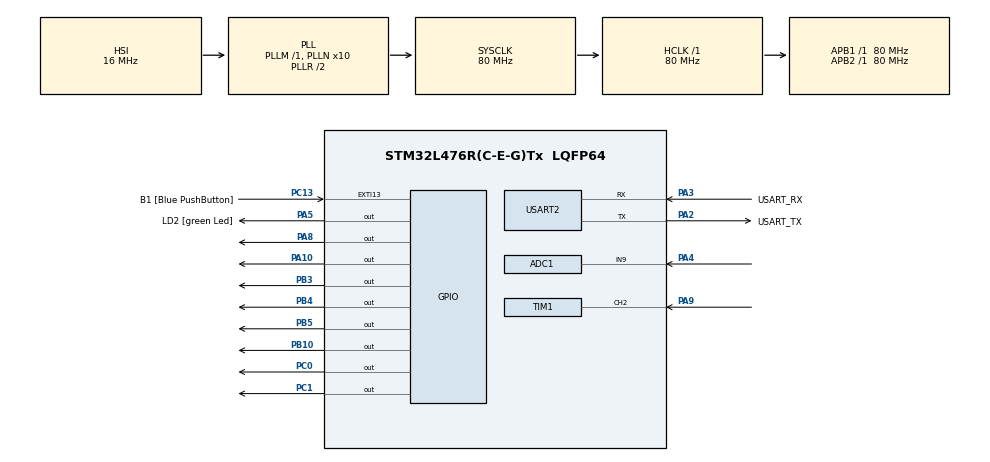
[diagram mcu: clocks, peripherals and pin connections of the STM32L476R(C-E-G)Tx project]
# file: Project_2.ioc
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ADC1.Channel-0\#ChannelRegularConversion=ADC_CHANNEL_9
ADC1.ClockPrescaler=ADC_CLOCK_ASYNC_DIV256
ADC1.ContinuousConvMode=ENABLE
ADC1.NbrOfConversionFlag=1
ADC1.OffsetNumber-0\#ChannelRegularConversion=ADC_OFFSET_NONE
ADC1.Rank-0\#ChannelRegularConversion=1
ADC1.SamplingTime-0\#ChannelRegularConversion=ADC_SAMPLETIME_2CYCLES_5
ADC1.master=1
Mcu.Family=STM32L4
Mcu.Name=STM32L476R(C-E-G)Tx
Mcu.Package=LQFP64
NVIC.ADC1_2_IRQn=true\:0\:0\:false\:true\:true\:1\:true\:true
NVIC.PriorityGroup=NVIC_PRIORITYGROUP_4
NVIC.TIM1_CC_IRQn=true\:0\:0\:false\:true\:true\:2\:true\:true
NVIC.TIM6_DAC_IRQn=true\:0\:0\:false\:true\:true\:4\:true\:true
NVIC.USART2_IRQn=true\:0\:0\:false\:true\:true\:3\:true\:true
PA10.Signal=GPIO_Output
PA13\ (JTMS-SWDIO).GPIO_Label=TMS
PA13\ (JTMS-SWDIO).Mode=Serial_Wire
PA13\ (JTMS-SWDIO).Signal=SYS_JTMS-SWDIO
PA14\ (JTCK-SWCLK).GPIO_Label=TCK
PA14\ (JTCK-SWCLK).Mode=Serial_Wire
PA14\ (JTCK-SWCLK).Signal=SYS_JTCK-SWCLK
PA2.GPIO_Label=USART_TX
PA2.GPIO_Mode=GPIO_MODE_AF_PP
PA2.GPIO_PuPd=GPIO_NOPULL
PA2.GPIO_Speed=GPIO_SPEED_FREQ_VERY_HIGH
PA2.Mode=Asynchronous
PA2.Signal=USART2_TX
PA3.GPIO_Label=USART_RX
PA3.GPIO_Mode=GPIO_MODE_AF_PP
PA3.GPIO_PuPd=GPIO_NOPULL
PA3.GPIO_Speed=GPIO_SPEED_FREQ_VERY_HIGH
PA3.Mode=Asynchronous
PA3.Signal=USART2_RX
PA4.Signal=ADCx_IN9
PA5.GPIO_Label=LD2 [green Led]
PA5.GPIO_ModeDefaultOutputPP=GPIO_MODE_OUTPUT_PP
PA5.GPIO_PuPd=GPIO_NOPULL
PA5.GPIO_Speed=GPIO_SPEED_FREQ_LOW
PA5.Signal=GPIO_Output
PA8.Signal=GPIO_Output
PA9.Signal=S_TIM1_CH2
PB10.Signal=GPIO_Output
PB3\ (JTDO-TRACESWO).Signal=GPIO_Output
PB4\ (NJTRST).Signal=GPIO_Output
PB5.Signal=GPIO_Output
PC0.Signal=GPIO_Output
PC1.Signal=GPIO_Output
PC13.GPIO_Label=B1 [Blue PushButton]
PC13.GPIO_ModeDefaultEXTI=GPIO_MODE_IT_FALLING
PC13.GPIO_PuPd=GPIO_NOPULL
PC13.Signal=GPXTI13
PC14-OSC32_IN\ (PC14).Mode=LSE-External-Oscillator
PC14-OSC32_IN\ (PC14).Signal=RCC_OSC32_IN
PC15-OSC32_OUT\ (PC15).Mode=LSE-External-Oscillator
PC15-OSC32_OUT\ (PC15).Signal=RCC_OSC32_OUT
PH0-OSC_IN\ (PH0).Signal=RCC_OSC_IN
PH1-OSC_OUT\ (PH1).Signal=RCC_OSC_OUT
ProjectManager.HeapSize=0x200
ProjectManager.StackSize=0x400
ProjectManager.TargetToolchain=STM32CubeIDE
RCC.ADCFreq_Value=64000000
RCC.AHBFreq_Value=80000000
RCC.APB1Freq_Value=80000000
RCC.APB1TimFreq_Value=80000000
RCC.APB2Freq_Value=80000000
RCC.APB2TimFreq_Value=80000000
RCC.CortexFreq_Value=80000000
RCC.HCLKFreq_Value=80000000
RCC.HSE_VALUE=8000000
RCC.HSI_VALUE=16000000
RCC.MSI_VALUE=4000000
RCC.PLLN=10
RCC.PLLSourceVirtual=RCC_PLLSOURCE_HSI
RCC.PREFETCH_ENABLE=1
RCC.SYSCLKFreq_VALUE=80000000
RCC.SYSCLKSource=RCC_SYSCLKSOURCE_PLLCLK
RCC.USBFreq_Value=64000000
RCC.VCOOutputFreq_Value=160000000
SH.ADCx_IN9.0=ADC1_IN9,IN9-Single-Ended
SH.S_TIM1_CH2.0=TIM1_CH2,Input_Capture2_from_TI2
TIM1.Channel-Input_Capture2_from_TI2=TIM_CHANNEL_2
TIM1.Period=0xFFFF
TIM1.Prescaler=80-1
TIM6.Period=0xFFFF
TIM6.Prescaler=80-1
USART2.VirtualMode-Asynchronous=VM_ASYNC
VP_TIM6_VS_ClockSourceINT.Mode=Enable_Timer
board=NUCLEO-L476RG

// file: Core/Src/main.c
#include "main.h"

typedef struct{
	GPIO_TypeDef* GPIO_x;
	uint16_t GPIO_Pin;
}GPIO_TYPE;

#define PA10 		(GPIO_TYPE){.GPIO_x = GPIOA, .GPIO_Pin=GPIO_PIN_10}
#define PB3 		(GPIO_TYPE){.GPIO_x = GPIOB, .GPIO_Pin=GPIO_PIN_3}
#define PB5 		(GPIO_TYPE){.GPIO_x = GPIOB, .GPIO_Pin=GPIO_PIN_5}
#define PB4 		(GPIO_TYPE){.GPIO_x = GPIOB, .GPIO_Pin=GPIO_PIN_4}
#define PB10 		(GPIO_TYPE){.GPIO_x = GPIOB, .GPIO_Pin=GPIO_PIN_10}
#define PA8 		(GPIO_TYPE){.GPIO_x = GPIOA, .GPIO_Pin=GPIO_PIN_8}
#define PC1 		(GPIO_TYPE){.GPIO_x = GPIOC, .GPIO_Pin=GPIO_PIN_1}
#define PC0 		(GPIO_TYPE){.GPIO_x = GPIOC, .GPIO_Pin=GPIO_PIN_0}

ADC_HandleTypeDef hadc1;
TIM_HandleTypeDef htim1;
TIM_HandleTypeDef htim6;
UART_HandleTypeDef huart2;

/* Global variables. START ------------------------------------------------- */
// LED array
const GPIO_TYPE GPIO_ARRAY[8] = {PA10, PB3, PB5, PB4, PB10, PA8, PC1, PC0};

// USART2
uint8_t msg[50]="";
char Rx_Char;

// TIM6
int reverse = 0;
int gpio_pin_index = 0;
int tim6_period = 10000; //default period of 10000 (1 sec)

// ADC1
uint32_t ADC_Status;
uint32_t ADC_Result;
float ADC_Voltage;
int previous = -1, current = 1;

// TIM1 IC
uint32_t IC_Value1 = 0,
		IC_Value2 = 0,
		Difference = 0,
		Frequency = 0;
uint8_t Is_First_Captured = 0;

// Continuous modes flag
char continuous_cmd;
uint8_t Is_Continuous_Mode_ON = 0;

/* Global variables. END ---------------------------------------------------- */

void SystemClock_Config(void);
static void MX_GPIO_Init(void);
static void MX_USART2_UART_Init(void);
static void MX_TIM1_Init(void);
static void MX_ADC1_Init(void);
static void MX_TIM6_Init(void);
static void MX_NVIC_Init(void);
void USART2_write(int c);
void USART_PRINT(char *msg);

void Interrupts_start(void){
	HAL_TIM_IC_Start_IT(&htim1, TIM_CHANNEL_2);
	HAL_TIM_Base_Start_IT(&htim6);
	HAL_ADC_Start_IT(&hadc1);

	__disable_irq();
	USART2->CR1 |= 0x00000020;
	NVIC_EnableIRQ(USART2_IRQn);
	__enable_irq();
}

/* TIM1 CH2 Interrupts */
void HAL_TIM_IC_CaptureCallback(TIM_HandleTypeDef *htim) {
	if(htim->Channel == HAL_TIM_ACTIVE_CHANNEL_2){
		if(Is_First_Captured == 0){
			IC_Value1 =  HAL_TIM_ReadCapturedValue(htim, TIM_CHANNEL_2);
			Is_First_Captured=1;
		}else if(Is_First_Captured==1){
			IC_Value2 = HAL_TIM_ReadCapturedValue(htim, TIM_CHANNEL_2);
			if(IC_Value2 > IC_Value1){
				Difference = IC_Value2 - IC_Value1;
			}else if(IC_Value2<IC_Value1){
				Difference = ((0xffff-IC_Value1)+IC_Value2)+1;
			}else{
				Error_Handler();
			}
			Frequency = HAL_RCC_GetPCLK1Freq()/Difference;
			Is_First_Captured = 0;
		}

	}
}

/* TIM6 Interrupts Cylon led display*/
void HAL_TIM_PeriodElapsedCallback(TIM_HandleTypeDef *htim){
	if(reverse == 0){
		if(gpio_pin_index==0){
			HAL_GPIO_TogglePin(GPIO_ARRAY[gpio_pin_index].GPIO_x, GPIO_ARRAY[gpio_pin_index].GPIO_Pin);
		}else{
			HAL_GPIO_TogglePin(GPIO_ARRAY[gpio_pin_index-1].GPIO_x, GPIO_ARRAY[gpio_pin_index-1].GPIO_Pin);
			HAL_GPIO_TogglePin(GPIO_ARRAY[gpio_pin_index].GPIO_x, GPIO_ARRAY[gpio_pin_index].GPIO_Pin);
		}
		gpio_pin_index++;
		if(gpio_pin_index>7){
			reverse=1;
			gpio_pin_index--;
		}
	}else{
		HAL_GPIO_TogglePin(GPIO_ARRAY[gpio_pin_index].GPIO_x, GPIO_ARRAY[gpio_pin_index].GPIO_Pin);
		HAL_GPIO_TogglePin(GPIO_ARRAY[gpio_pin_index-1].GPIO_x, GPIO_ARRAY[gpio_pin_index-1].GPIO_Pin);
		gpio_pin_index--;
		if(gpio_pin_index==0){
			reverse=0;
			gpio_pin_index++;
		}
	}
}

/* USART2 input Interrupts */
void USART2_IRQHandler(void)
{
	HAL_UART_IRQHandler(&huart2);
	/* USER CODE BEGIN USART2_IRQn 1 */
	if (USART2->ISR & 0x0020) {
		Rx_Char = USART2->RDR;
	}
}

/* ADC interrupts. */
void HAL_ADC_ConvCpltCallback(ADC_HandleTypeDef *hadc)
{
	HAL_ADC_Start(&hadc1);
	ADC_Status = HAL_ADC_PollForConversion(&hadc1, 100);
	if (ADC_Status == HAL_OK)
	{
	  ADC_Result = HAL_ADC_GetValue(&hadc1);
	}
	ADC_Voltage = (float)ADC_Result  * 3.3 / 4095.0;
	if(ADC_Voltage<1){
		tim6_period = 2500;
		current = 0;
	}else{
		tim6_period = 10000;
		current = 1;
	}
	if(previous !=  current){
		MX_TIM6_Init();
		previous = current;
	}
//	HAL_Delay(50);
}

int main(void)
{
  /* Reset of all peripherals, Initializes the Flash interface and the Systick. */
  HAL_Init();
  /* Configure the system clock */
  SystemClock_Config();
  /* Initialize all configured peripherals */
  MX_GPIO_Init();
  MX_USART2_UART_Init();
  MX_TIM1_Init();
  MX_ADC1_Init();
  MX_TIM6_Init();
  /* Initialize interrupts */
  MX_NVIC_Init();

  /* Interrupts start. */
  Interrupts_start();

  /* Infinite loop */
  while (1)
  {
	  // check if Continuous mode is on or not
	  if(Is_Continuous_Mode_ON==1){
		  // check if Continuous mode cmd
		  if(continuous_cmd=='C' || continuous_cmd=='c'){
			  // check if usart captured cmd
			  if(!(Rx_Char=='E' || Rx_Char=='e') && !(Rx_Char=='C' || Rx_Char=='c')){
				  Rx_Char = continuous_cmd;
				  strcpy(msg, "Continuous Mode is ON, enter E/e to stop!");
				  USART_PRINT(msg);
			  }
		  }else if(continuous_cmd=='W' || continuous_cmd=='w'){
			  if(!(Rx_Char=='Q' || Rx_Char=='q') && !(Rx_Char=='W' || Rx_Char=='w')){
				  Rx_Char = continuous_cmd;
				  strcpy(msg, "Continuous Mode is ON, enter Q/q to stop!");
				  USART_PRINT(msg);
			  }
		  }
	  }
	  switch(Rx_Char){
		case 'A':
		case 'a':
			sprintf(msg, "ADC Result = %d", ADC_Result);
			USART_PRINT(msg);
			Rx_Char='\0';
			break;
		case 'V':
		case 'v':
			sprintf(msg, "ADC Voltage = %.2f", ADC_Voltage);
			USART_PRINT(msg);
			Rx_Char='\0';
			break;
		case 'T':
		case 't':
			sprintf(msg, "Timer output Period = %d us", Difference);
			USART_PRINT(msg);
			Rx_Char='\0';
			break;
		case 'F':
		case 'f':
			sprintf(msg, "Timer output Frequency = %.2f kHz", (float)Frequency/1000);
			USART_PRINT(msg);
			Rx_Char='\0';
			break;
		case 'C':
		case 'c':
			sprintf(msg, "ADC Voltage = %.2f", ADC_Voltage);
			USART_PRINT(msg);
			continuous_cmd='c';
			Is_Continuous_Mode_ON=1;
			HAL_Delay(1000);
			break;
		case 'W':
		case 'w':
			sprintf(msg, "Timer output Frequency = %.2f kHz", (float)Frequency/1000);
			USART_PRINT(msg);
			continuous_cmd='w';
			Is_Continuous_Mode_ON=1;
			HAL_Delay(1000);
			break;
		case 'E':
		case 'e':
		case 'Q':
		case 'q':
			Is_Continuous_Mode_ON=0;
			Rx_Char='\0';
			break;
		default:
			break;
		}
//		HAL_Delay(1000);
  }

}

/* Write a character to USART2 */
void USART2_write (int ch) {
    while (!(USART2->ISR & 0x0080)) {}   // wait until Tx buffer empty
    USART2->TDR = (ch & 0xFF);
}

void USART_PRINT(char *buffer){
	for(int i=0; i<strlen(buffer);i++){
		USART2_write(buffer[i]);
	}
	USART2_write('\r');
	USART2_write('\n');
}

void SystemClock_Config(void)
{
  RCC_OscInitTypeDef RCC_OscInitStruct = {0};
  RCC_ClkInitTypeDef RCC_ClkInitStruct = {0};
  RCC_PeriphCLKInitTypeDef PeriphClkInit = {0};

  /** Initializes the CPU, AHB and APB busses clocks
  */
  RCC_OscInitStruct.OscillatorType = RCC_OSCILLATORTYPE_HSI;
  RCC_OscInitStruct.HSIState = RCC_HSI_ON;
  RCC_OscInitStruct.HSICalibrationValue = RCC_HSICALIBRATION_DEFAULT;
  RCC_OscInitStruct.PLL.PLLState = RCC_PLL_ON;
  RCC_OscInitStruct.PLL.PLLSource = RCC_PLLSOURCE_HSI;
  RCC_OscInitStruct.PLL.PLLM = 1;
  RCC_OscInitStruct.PLL.PLLN = 10;
  RCC_OscInitStruct.PLL.PLLP = RCC_PLLP_DIV7;
  RCC_OscInitStruct.PLL.PLLQ = RCC_PLLQ_DIV2;
  RCC_OscInitStruct.PLL.PLLR = RCC_PLLR_DIV2;
  if (HAL_RCC_OscConfig(&RCC_OscInitStruct) != HAL_OK)
  {
    Error_Handler();
  }
  /** Initializes the CPU, AHB and APB busses clocks
  */
  RCC_ClkInitStruct.ClockType = RCC_CLOCKTYPE_HCLK|RCC_CLOCKTYPE_SYSCLK
                              |RCC_CLOCKTYPE_PCLK1|RCC_CLOCKTYPE_PCLK2;
  RCC_ClkInitStruct.SYSCLKSource = RCC_SYSCLKSOURCE_PLLCLK;
  RCC_ClkInitStruct.AHBCLKDivider = RCC_SYSCLK_DIV1;
  RCC_ClkInitStruct.APB1CLKDivider = RCC_HCLK_DIV1;
  RCC_ClkInitStruct.APB2CLKDivider = RCC_HCLK_DIV1;

  if (HAL_RCC_ClockConfig(&RCC_ClkInitStruct, FLASH_LATENCY_4) != HAL_OK)
  {
    Error_Handler();
  }
  PeriphClkInit.PeriphClockSelection = RCC_PERIPHCLK_USART2|RCC_PERIPHCLK_ADC;
  PeriphClkInit.Usart2ClockSelection = RCC_USART2CLKSOURCE_PCLK1;
  PeriphClkInit.AdcClockSelection = RCC_ADCCLKSOURCE_PLLSAI1;
  PeriphClkInit.PLLSAI1.PLLSAI1Source = RCC_PLLSOURCE_HSI;
  PeriphClkInit.PLLSAI1.PLLSAI1M = 1;
  PeriphClkInit.PLLSAI1.PLLSAI1N = 8;
  PeriphClkInit.PLLSAI1.PLLSAI1P = RCC_PLLP_DIV7;
  PeriphClkInit.PLLSAI1.PLLSAI1Q = RCC_PLLQ_DIV2;
  PeriphClkInit.PLLSAI1.PLLSAI1R = RCC_PLLR_DIV2;
  PeriphClkInit.PLLSAI1.PLLSAI1ClockOut = RCC_PLLSAI1_ADC1CLK;
  if (HAL_RCCEx_PeriphCLKConfig(&PeriphClkInit) != HAL_OK)
  {
    Error_Handler();
  }
  /** Configure the main internal regulator output voltage
  */
  if (HAL_PWREx_ControlVoltageScaling(PWR_REGULATOR_VOLTAGE_SCALE1) != HAL_OK)
  {
    Error_Handler();
  }
}

/**
  * @brief NVIC Configuration.
  * @retval None
  */
static void MX_NVIC_Init(void)
{
  /* ADC1_2_IRQn interrupt configuration */
  HAL_NVIC_SetPriority(ADC1_2_IRQn, 0, 0);
  HAL_NVIC_EnableIRQ(ADC1_2_IRQn);
  /* TIM1_CC_IRQn interrupt configuration */
  HAL_NVIC_SetPriority(TIM1_CC_IRQn, 0, 0);
  HAL_NVIC_EnableIRQ(TIM1_CC_IRQn);
  /* USART2_IRQn interrupt configuration */
  HAL_NVIC_SetPriority(USART2_IRQn, 0, 0);
  HAL_NVIC_EnableIRQ(USART2_IRQn);
  /* TIM6_DAC_IRQn interrupt configuration */
  HAL_NVIC_SetPriority(TIM6_DAC_IRQn, 0, 0);
  HAL_NVIC_EnableIRQ(TIM6_DAC_IRQn);
}

static void MX_ADC1_Init(void)
{

  ADC_MultiModeTypeDef multimode = {0};
  ADC_ChannelConfTypeDef sConfig = {0};

  /** Common config
  */
  hadc1.Instance = ADC1;
  hadc1.Init.ClockPrescaler = ADC_CLOCK_ASYNC_DIV256;
  hadc1.Init.Resolution = ADC_RESOLUTION_12B;
  hadc1.Init.DataAlign = ADC_DATAALIGN_RIGHT;
  hadc1.Init.ScanConvMode = ADC_SCAN_DISABLE;
  hadc1.Init.EOCSelection = ADC_EOC_SINGLE_CONV;
  hadc1.Init.LowPowerAutoWait = DISABLE;
  hadc1.Init.ContinuousConvMode = ENABLE;
  hadc1.Init.NbrOfConversion = 1;
  hadc1.Init.DiscontinuousConvMode = DISABLE;
  hadc1.Init.NbrOfDiscConversion = 1;
  hadc1.Init.ExternalTrigConv = ADC_SOFTWARE_START;
  hadc1.Init.ExternalTrigConvEdge = ADC_EXTERNALTRIGCONVEDGE_NONE;
  hadc1.Init.DMAContinuousRequests = DISABLE;
  hadc1.Init.Overrun = ADC_OVR_DATA_PRESERVED;
  hadc1.Init.OversamplingMode = DISABLE;
  if (HAL_ADC_Init(&hadc1) != HAL_OK)
  {
    Error_Handler();
  }
  /** Configure the ADC multi-mode
  */
  multimode.DMAAccessMode = ADC_DMAACCESSMODE_DISABLED;
  multimode.TwoSamplingDelay = ADC_TWOSAMPLINGDELAY_1CYCLE;
  if (HAL_ADCEx_MultiModeConfigChannel(&hadc1, &multimode) != HAL_OK)
  {
    Error_Handler();
  }
  /** Configure Regular Channel
  */
  sConfig.Channel = ADC_CHANNEL_9;
  sConfig.Rank = ADC_REGULAR_RANK_1;
  sConfig.SamplingTime = ADC_SAMPLETIME_2CYCLES_5;
  sConfig.SingleDiff = ADC_SINGLE_ENDED;
  sConfig.OffsetNumber = ADC_OFFSET_NONE;
  sConfig.Offset = 0;
  if (HAL_ADC_ConfigChannel(&hadc1, &sConfig) != HAL_OK)
  {
    Error_Handler();
  }
  /* USER CODE BEGIN ADC1_Init 2 */
//  HAL_ADC_Start_IT(&hadc1);
  /* USER CODE END ADC1_Init 2 */

}

static void MX_TIM1_Init(void)
{

  TIM_MasterConfigTypeDef sMasterConfig = {0};
  TIM_IC_InitTypeDef sConfigIC = {0};

  htim1.Instance = TIM1;
  htim1.Init.Prescaler = 80-1;
  htim1.Init.CounterMode = TIM_COUNTERMODE_UP;
  htim1.Init.Period = 0xFFFF;
  htim1.Init.ClockDivision = TIM_CLOCKDIVISION_DIV1;
  htim1.Init.RepetitionCounter = 0;
  htim1.Init.AutoReloadPreload = TIM_AUTORELOAD_PRELOAD_DISABLE;
  if (HAL_TIM_IC_Init(&htim1) != HAL_OK)
  {
    Error_Handler();
  }
  sMasterConfig.MasterOutputTrigger = TIM_TRGO_RESET;
  sMasterConfig.MasterOutputTrigger2 = TIM_TRGO2_RESET;
  sMasterConfig.MasterSlaveMode = TIM_MASTERSLAVEMODE_DISABLE;
  if (HAL_TIMEx_MasterConfigSynchronization(&htim1, &sMasterConfig) != HAL_OK)
  {
    Error_Handler();
  }
  sConfigIC.ICPolarity = TIM_INPUTCHANNELPOLARITY_RISING;
  sConfigIC.ICSelection = TIM_ICSELECTION_DIRECTTI;
  sConfigIC.ICPrescaler = TIM_ICPSC_DIV1;
  sConfigIC.ICFilter = 0;
  if (HAL_TIM_IC_ConfigChannel(&htim1, &sConfigIC, TIM_CHANNEL_2) != HAL_OK)
  {
    Error_Handler();
  }

}

static void MX_TIM6_Init(void)
{

  TIM_MasterConfigTypeDef sMasterConfig = {0};

  htim6.Instance = TIM6;
  htim6.Init.Prescaler = 8000-1;
  htim6.Init.CounterMode = TIM_COUNTERMODE_UP;
  htim6.Init.Period = tim6_period-1;
  htim6.Init.AutoReloadPreload = TIM_AUTORELOAD_PRELOAD_DISABLE;
  if (HAL_TIM_Base_Init(&htim6) != HAL_OK)
  {
    Error_Handler();
  }
  sMasterConfig.MasterOutputTrigger = TIM_TRGO_RESET;
  sMasterConfig.MasterSlaveMode = TIM_MASTERSLAVEMODE_DISABLE;
  if (HAL_TIMEx_MasterConfigSynchronization(&htim6, &sMasterConfig) != HAL_OK)
  {
    Error_Handler();
  }
  /* USER CODE BEGIN TIM6_Init 2 */
//  HAL_TIM_Base_Start_IT(&htim6);
  /* USER CODE END TIM6_Init 2 */

}

static void MX_USART2_UART_Init(void)
{

  huart2.Instance = USART2;
  huart2.Init.BaudRate = 115200;
  huart2.Init.WordLength = UART_WORDLENGTH_8B;
  huart2.Init.StopBits = UART_STOPBITS_1;
  huart2.Init.Parity = UART_PARITY_NONE;
  huart2.Init.Mode = UART_MODE_TX_RX;
  huart2.Init.HwFlowCtl = UART_HWCONTROL_NONE;
  huart2.Init.OverSampling = UART_OVERSAMPLING_16;
  huart2.Init.OneBitSampling = UART_ONE_BIT_SAMPLE_DISABLE;
  huart2.AdvancedInit.AdvFeatureInit = UART_ADVFEATURE_NO_INIT;
  if (HAL_UART_Init(&huart2) != HAL_OK)
  {
    Error_Handler();
  }

}

static void MX_GPIO_Init(void)
{
  GPIO_InitTypeDef GPIO_InitStruct = {0};

  /* GPIO Ports Clock Enable */
  __HAL_RCC_GPIOC_CLK_ENABLE();
  __HAL_RCC_GPIOH_CLK_ENABLE();
  __HAL_RCC_GPIOA_CLK_ENABLE();
  __HAL_RCC_GPIOB_CLK_ENABLE();

  /*Configure GPIO pin Output Level */
  HAL_GPIO_WritePin(GPIOC, GPIO_PIN_0|GPIO_PIN_1, GPIO_PIN_RESET);

  /*Configure GPIO pin Output Level */
  HAL_GPIO_WritePin(GPIOA, LD2_Pin|GPIO_PIN_8|GPIO_PIN_10, GPIO_PIN_RESET);

  /*Configure GPIO pin Output Level */
  HAL_GPIO_WritePin(GPIOB, GPIO_PIN_10|GPIO_PIN_3|GPIO_PIN_4|GPIO_PIN_5, GPIO_PIN_RESET);

  /*Configure GPIO pin : B1_Pin */
  GPIO_InitStruct.Pin = B1_Pin;
  GPIO_InitStruct.Mode = GPIO_MODE_IT_FALLING;
  GPIO_InitStruct.Pull = GPIO_NOPULL;
  HAL_GPIO_Init(B1_GPIO_Port, &GPIO_InitStruct);

  /*Configure GPIO pins : PC0 PC1 */
  GPIO_InitStruct.Pin = GPIO_PIN_0|GPIO_PIN_1;
  GPIO_InitStruct.Mode = GPIO_MODE_OUTPUT_PP;
  GPIO_InitStruct.Pull = GPIO_NOPULL;
  GPIO_InitStruct.Speed = GPIO_SPEED_FREQ_LOW;
  HAL_GPIO_Init(GPIOC, &GPIO_InitStruct);

  /*Configure GPIO pins : LD2_Pin PA8 PA10 */
  GPIO_InitStruct.Pin = LD2_Pin|GPIO_PIN_8|GPIO_PIN_10;
  GPIO_InitStruct.Mode = GPIO_MODE_OUTPUT_PP;
  GPIO_InitStruct.Pull = GPIO_NOPULL;
  GPIO_InitStruct.Speed = GPIO_SPEED_FREQ_LOW;
  HAL_GPIO_Init(GPIOA, &GPIO_InitStruct);

  /*Configure GPIO pins : PB10 PB3 PB4 PB5 */
  GPIO_InitStruct.Pin = GPIO_PIN_10|GPIO_PIN_3|GPIO_PIN_4|GPIO_PIN_5;
  GPIO_InitStruct.Mode = GPIO_MODE_OUTPUT_PP;
  GPIO_InitStruct.Pull = GPIO_NOPULL;
  GPIO_InitStruct.Speed = GPIO_SPEED_FREQ_LOW;
  HAL_GPIO_Init(GPIOB, &GPIO_InitStruct);

}

void Error_Handler(void)
{
}

/************************ (C) COPYRIGHT STMicroelectronics *****END OF FILE****/
